# EFR32BG13P632F512IM48 register map
File version: 4.0.0
CPU: CM4 r0p1, little endian, MPU, FPU, 3 interrupt priority bits
Registers are 32-bit, read-write, reset 0x0 unless marked. A register's access mark holds for its fields unless they carry their own. Offsets are from the block's base; [hi:lo] are bit positions.

## SMU
Base 0x40022000
0x0C IF ro — Interrupt Flag Register
  [0] PPUPRIV — PPU Privilege Interrupt Flag
0x10 IFS wo — Interrupt Flag Set Register
  [0] PPUPRIV — Set PPUPRIV Interrupt Flag
0x14 IFC wo — Interrupt Flag Clear Register
  [0] PPUPRIV — Clear PPUPRIV Interrupt Flag
0x18 IEN — Interrupt Enable Register
  [0] PPUPRIV — PPUPRIV Interrupt Enable
0x40 PPUCTRL — PPU Control Register
  [0] ENABLE
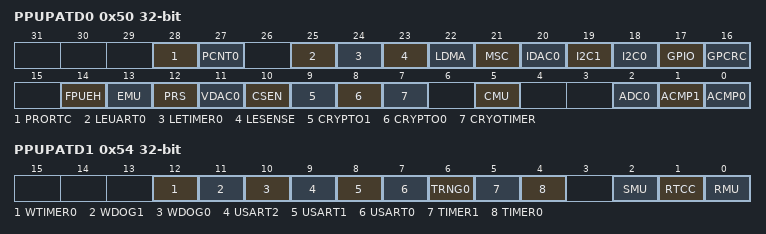
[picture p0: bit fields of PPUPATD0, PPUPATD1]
0x50 PPUPATD0 — PPU Privilege Access Type Descriptor 0
  [28] PRORTC — Protocol Real-Time Counter access control bit
  [27] PCNT0 — Pulse Counter 0 access control bit
  [25] LEUART0 — Low Energy UART 0 access control bit
  [24] LETIMER0 — Low Energy Timer 0 access control bit
  [23] LESENSE — Low Energy Sensor Interface access control bit
  [22] LDMA — Linked Direct Memory Access Controller access control bit
  [21] MSC — Memory System Controller access control bit
  [20] IDAC0 — Current Digital to Analog Converter 0 access control bit
  [19] I2C1 — I2C 1 access control bit
  [18] I2C0 — I2C 0 access control bit
  [17] GPIO — General purpose Input/Output access control bit
  [16] GPCRC — General Purpose CRC access control bit
  [14] FPUEH — FPU Exception Handler access control bit
  [13] EMU — Energy Management Unit access control bit
  [12] PRS — Peripheral Reflex System access control bit
  [11] VDAC0 — Digital to Analog Converter 0 access control bit
  [10] CSEN — Capacitive touch sense module access control bit
  [9] CRYPTO1 — Advanced Encryption Standard Accelerator 1 access control bit
  [8] CRYPTO0 — Advanced Encryption Standard Accelerator 0 access control bit
  [7] CRYOTIMER — CRYOTIMER access control bit
  [5] CMU — Clock Management Unit access control bit
  [2] ADC0 — Analog to Digital Converter 0 access control bit
  [1] ACMP1 — Analog Comparator 1 access control bit
  [0] ACMP0 — Analog Comparator 0 access control bit
0x54 PPUPATD1 — PPU Privilege Access Type Descriptor 1
  [12] WTIMER0 — Wide Timer 0 access control bit
  [11] WDOG1 — Watchdog 1 access control bit
  [10] WDOG0 — Watchdog 0 access control bit
  [9] USART2 — Universal Synchronous/Asynchronous Receiver/Transmitter 2 access control bit
  [8] USART1 — Universal Synchronous/Asynchronous Receiver/Transmitter 1 access control bit
  [7] USART0 — Universal Synchronous/Asynchronous Receiver/Transmitter 0 access control bit
  [6] TRNG0 — True Random Number Generator 0 access control bit
  [5] TIMER1 — Timer 1 access control bit
  [4] TIMER0 — Timer 0 access control bit
  [2] SMU — Security Management Unit access control bit
  [1] RTCC — Real-Time Counter and Calendar access control bit
  [0] RMU — Reset Management Unit access control bit
0x90 PPUFS ro — PPU Fault Status
  [6:0] PERIPHID
    0=ACMP0 (Analog Comparator 0); 1=ACMP1 (Analog Comparator 1); 2=ADC0 (Analog to Digital Converter 0); 5=CMU (Clock Management Unit); 7=CRYOTIMER; 8=CRYPTO0 (Advanced Encryption Standard Accelerator 0); 9=CRYPTO1 (Advanced Encryption Standard Accelerator 1); 10=CSEN (Capacitive touch sense module); 11=VDAC0 (Digital to Analog Converter 0); 12=PRS (Peripheral Reflex System); 13=EMU (Energy Management Unit); 14=FPUEH (FPU Exception Handler); 16=GPCRC (General Purpose CRC); 17=GPIO (General purpose Input/Output); 18=I2C0; 19=I2C1; 20=IDAC0 (Current Digital to Analog Converter 0); 21=MSC (Memory System Controller); 22=LDMA (Linked Direct Memory Access Controller); 23=LESENSE (Low Energy Sensor Interface); 24=LETIMER0 (Low Energy Timer 0); 25=LEUART0 (Low Energy UART 0); 27=PCNT0 (Pulse Counter 0); 28=PRORTC (Protocol Real-Time Counter); 32=RMU (Reset Management Unit); 33=RTCC (Real-Time Counter and Calendar); 34=SMU (Security Management Unit); 36=TIMER0; 37=TIMER1; 38=TRNG0 (True Random Number Generator 0); 39=USART0 (Universal Synchronous/Asynchronous Receiver/Transmitter 0); 40=USART1 (Universal Synchronous/Asynchronous Receiver/Transmitter 1); 41=USART2 (Universal Synchronous/Asynchronous Receiver/Transmitter 2); 42=WDOG0 (Watchdog 0); 43=WDOG1 (Watchdog 1); 44=WTIMER0 (Wide Timer 0)

## Notices in the file
# License
Copyright 2021 Silicon Laboratories Inc. www.silabs.com
SPDX-License-Identifier: Zlib
The licensor of this software is Silicon Laboratories Inc.
This software is provided 'as-is', without any express or implied
warranty. In no event will the authors be held liable for any damages
arising from the use of this software.
Permission is granted to anyone to use this software for any purpose,
including commercial applications, and to alter it and redistribute it
freely, subject to the following restrictions:
1. The origin of this software must not be misrepresented; you must not
claim that you wrote the original software. If you use this software
in a product, an acknowledgment in the product documentation would be
appreciated but is not required.
2. Altered source versions must be plainly marked as such, and must not be
misrepresented as being the original software.
3. This notice may not be removed or altered from any source distribution.
